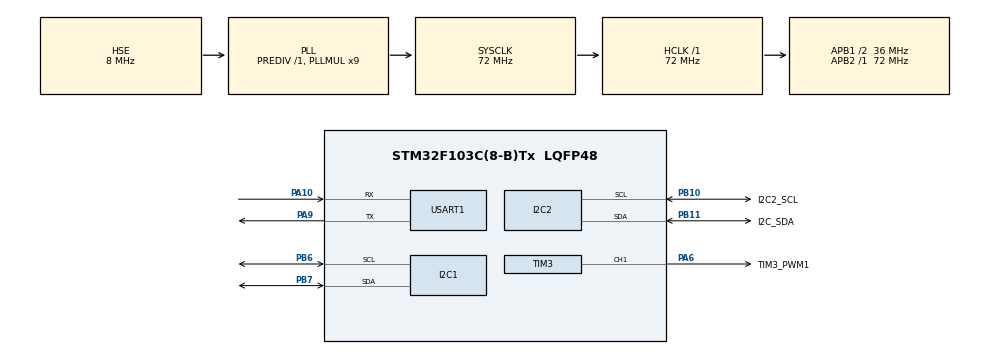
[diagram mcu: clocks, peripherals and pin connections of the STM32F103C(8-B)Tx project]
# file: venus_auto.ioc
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Mcu.Family=STM32F1
RCC.PLLSourceVirtual=RCC_PLLSOURCE_HSE
FREERTOS.Tasks01=DAQ,24,128,StartDAQTask,Default,NULL,Dynamic,NULL,NULL;OsConfigTask,24,128,OsConfig,Default,NULL,Dynamic,NULL,NULL
PD1-OSC_OUT.Mode=HSE-External-Oscillator
PA10.Mode=Asynchronous
PB10.Mode=I2C
TIM3.AutoReloadPreload=TIM_AUTORELOAD_PRELOAD_ENABLE
PB11.GPIO_Label=I2C_SDA
PA6.GPIO_Label=TIM3_PWM1
PD0-OSC_IN.Signal=RCC_OSC_IN
RCC.APB1CLKDivider=RCC_HCLK_DIV2
PB11.Signal=I2C2_SDA
RCC.SYSCLKSource=RCC_SYSCLKSOURCE_PLLCLK
ProjectManager.StackSize=0x400
VP_FREERTOS_VS_CMSIS_V2.Mode=CMSIS_V2
PD1-OSC_OUT.Signal=RCC_OSC_OUT
PA13.Signal=SYS_JTMS-SWDIO
PA9.Mode=Asynchronous
TIM3.Pulse-PWM\ Generation1\ CH1=500
Mcu.UserConstants=BPM180_SCL,I2C2_SCL;BMP180_SDA,I2C2_SDA;DHT20_SCL,I2C1_SCL;DHT20_SDA,I2C1_SDA
PB11.Mode=I2C
ProjectManager.TargetToolchain=STM32CubeIDE
PB10.GPIO_Label=I2C2_SCL
I2C1.I2C_Mode=I2C_Fast
RCC.HCLKFreq_Value=72000000
I2C1.DutyCycle=I2C_DUTYCYCLE_16_9
RCC.APB2TimFreq_Value=72000000
TIM3.Period=999
PA9.Signal=USART1_TX
PB6.Signal=I2C1_SCL
PB6.Mode=I2C
NVIC.I2C2_ER_IRQn=true\:5\:0\:false\:false\:true\:true\:true\:true
RCC.USBFreq_Value=72000000
RCC.AHBFreq_Value=72000000
TIM3.Channel-PWM\ Generation1\ CH1=TIM_CHANNEL_1
PD0-OSC_IN.Mode=HSE-External-Oscillator
PB10.Signal=I2C2_SCL
board=custom
RCC.PLLMUL=RCC_PLL_MUL9
NVIC.TIM3_IRQn=true\:5\:0\:false\:false\:true\:true\:true\:true
RCC.APB2Freq_Value=72000000
PA14.Mode=Serial_Wire
TIM3.Prescaler=71
PB7.Signal=I2C1_SDA
SH.S_TIM3_CH1.0=TIM3_CH1,PWM Generation1 CH1
PA13.Mode=Serial_Wire
Mcu.Name=STM32F103C(8-B)Tx
TIM3.OCPolarity_1=TIM_OCPOLARITY_HIGH
RCC.SYSCLKFreq_VALUE=72000000
Mcu.Package=LQFP48
PA6.Signal=S_TIM3_CH1
NVIC.TimeBase=TIM4_IRQn
I2C2.DutyCycle=I2C_DUTYCYCLE_16_9
USART1.VirtualMode=VM_ASYNC
PB7.Mode=I2C
NVIC.TimeBaseIP=TIM4
PA10.Signal=USART1_RX
PA14.Signal=SYS_JTCK-SWCLK
ProjectManager.HeapSize=0x200
VP_SYS_VS_tim4.Mode=TIM4
NVIC.PriorityGroup=NVIC_PRIORITYGROUP_4
RCC.APB1TimFreq_Value=72000000
NVIC.USART1_IRQn=true\:5\:0\:false\:false\:true\:true\:true\:true
NVIC.TIM4_IRQn=true\:0\:0\:false\:false\:true\:false\:false\:true
RCC.APB1Freq_Value=36000000
I2C2.I2C_Mode=I2C_Fast
VP_TIM3_VS_ClockSourceINT.Mode=Internal

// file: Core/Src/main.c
/* USER CODE BEGIN Header */
/**
  ******************************************************************************
  * @file           : main.c
  * @brief          : Main program body
  ******************************************************************************
  * @attention
  *
  * <h2><center>&copy; Copyright (c) 2022 STMicroelectronics.
  * All rights reserved.</center></h2>
  *
  * This software component is licensed by ST under BSD 3-Clause license,
  * the "License"; You may not use this file except in compliance with the
  * License. You may obtain a copy of the License at:
  *                        opensource.org/licenses/BSD-3-Clause
  *
  ******************************************************************************
  */
/* USER CODE END Header */
#include "main.h"
#include "cmsis_os.h"
#include "i2c.h"
#include "tim.h"
#include "usart.h"
#include "gpio.h"

/* USER CODE BEGIN Includes */
#include "DAQ.h"
/* USER CODE END Includes */

void SystemClock_Config(void);
void MX_FREERTOS_Init(void);

int main(void)
{

  /* MCU Configuration--------------------------------------------------------*/

  /* Reset of all peripherals, Initializes the Flash interface and the Systick. */
  HAL_Init();

  /* Configure the system clock */
  SystemClock_Config();

  /* Initialize all configured peripherals */
  MX_GPIO_Init();
  MX_I2C2_Init();
  MX_I2C1_Init();
  MX_USART1_UART_Init();
  MX_TIM3_Init();

  /* Init scheduler */
  osKernelInitialize();  /* Call init function for freertos objects (in freertos.c) */
  MX_FREERTOS_Init();
  /* Start scheduler */
  osKernelStart();

  /* We should never get here as control is now taken by the scheduler */
  /* Infinite loop */
  while (1)
  {

  }
}

void SystemClock_Config(void)
{
  RCC_OscInitTypeDef RCC_OscInitStruct = {0};
  RCC_ClkInitTypeDef RCC_ClkInitStruct = {0};

  /** Initializes the RCC Oscillators according to the specified parameters
  * in the RCC_OscInitTypeDef structure.
  */
  RCC_OscInitStruct.OscillatorType = RCC_OSCILLATORTYPE_HSE;
  RCC_OscInitStruct.HSEState = RCC_HSE_ON;
  RCC_OscInitStruct.HSEPredivValue = RCC_HSE_PREDIV_DIV1;
  RCC_OscInitStruct.HSIState = RCC_HSI_ON;
  RCC_OscInitStruct.PLL.PLLState = RCC_PLL_ON;
  RCC_OscInitStruct.PLL.PLLSource = RCC_PLLSOURCE_HSE;
  RCC_OscInitStruct.PLL.PLLMUL = RCC_PLL_MUL9;
  if (HAL_RCC_OscConfig(&RCC_OscInitStruct) != HAL_OK)
  {
    Error_Handler();
  }
  /** Initializes the CPU, AHB and APB buses clocks
  */
  RCC_ClkInitStruct.ClockType = RCC_CLOCKTYPE_HCLK|RCC_CLOCKTYPE_SYSCLK
                              |RCC_CLOCKTYPE_PCLK1|RCC_CLOCKTYPE_PCLK2;
  RCC_ClkInitStruct.SYSCLKSource = RCC_SYSCLKSOURCE_PLLCLK;
  RCC_ClkInitStruct.AHBCLKDivider = RCC_SYSCLK_DIV1;
  RCC_ClkInitStruct.APB1CLKDivider = RCC_HCLK_DIV2;
  RCC_ClkInitStruct.APB2CLKDivider = RCC_HCLK_DIV1;

  if (HAL_RCC_ClockConfig(&RCC_ClkInitStruct, FLASH_LATENCY_2) != HAL_OK)
  {
    Error_Handler();
  }
}

 /**
  * @brief  Period elapsed callback in non blocking mode
  * @note   This function is called  when TIM4 interrupt took place, inside
  * HAL_TIM_IRQHandler(). It makes a direct call to HAL_IncTick() to increment
  * a global variable "uwTick" used as application time base.
  * @param  htim : TIM handle
  * @retval None
  */
void HAL_TIM_PeriodElapsedCallback(TIM_HandleTypeDef *htim)
{
  if (htim->Instance == TIM4) {
    HAL_IncTick();
  }
}

void Error_Handler(void)
{
  __disable_irq();
  while (1)
  {
  }
}

/************************ (C) COPYRIGHT STMicroelectronics *****END OF FILE****/

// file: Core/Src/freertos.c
/* USER CODE BEGIN Header */
/**
  ******************************************************************************
  * File Name          : freertos.c
  * Description        : Code for freertos applications
  ******************************************************************************
  * @attention
  *
  * <h2><center>&copy; Copyright (c) 2022 STMicroelectronics.
  * All rights reserved.</center></h2>
  *
  * This software component is licensed by ST under Ultimate Liberty license
  * SLA0044, the "License"; You may not use this file except in compliance with
  * the License. You may obtain a copy of the License at:
  *                             www.st.com/SLA0044
  *
  ******************************************************************************
  */
/* USER CODE END Header */

#include "FreeRTOS.h"
#include "task.h"
#include "main.h"
#include "cmsis_os.h"

/* USER CODE BEGIN Includes */
#include "DAQ.h"
#include "OsConfig.h"
/* USER CODE END Includes */

/* Definitions for DAQ */
osThreadId_t DAQHandle;
const osThreadAttr_t DAQ_attributes = {
  .name = "DAQ",
  .stack_size = 128 * 4,
  .priority = (osPriority_t) osPriorityNormal,
};
/* Definitions for OsConfigTask */
osThreadId_t OsConfigTaskHandle;
const osThreadAttr_t OsConfigTask_attributes = {
  .name = "OsConfigTask",
  .stack_size = 128 * 4,
  .priority = (osPriority_t) osPriorityNormal,
};

void StartDAQTask(void *argument);
void OsConfig(void *argument);

void MX_FREERTOS_Init(void); /* (MISRA C 2004 rule 8.1) */

void MX_FREERTOS_Init(void) {

  /* Create the thread(s) */
  /* creation of DAQ */
  DAQHandle = osThreadNew(StartDAQTask, NULL, &DAQ_attributes);

  /* creation of OsConfigTask */
  OsConfigTaskHandle = osThreadNew(OsConfig, NULL, &OsConfigTask_attributes);

}

void StartDAQTask(void *argument)
{
  /* USER CODE BEGIN StartDAQTask */
  DAQ_Init();

  /* Infinite loop */
  for(;;)
  {
	DAQ();

    osDelay(1000);
  }
  /* USER CODE END StartDAQTask */
}

void OsConfig(void *argument)
{
  /* USER CODE BEGIN OsConfig */

  OS_Config_Init();

  /* Infinite loop */
  for(;;)
  {
	OS_Config();
    osDelay(500);
  }
  /* USER CODE END OsConfig */
}

/************************ (C) COPYRIGHT STMicroelectronics *****END OF FILE****/
